# MEC1721N_B0_LJ register map
Vendor: Microchip Technology; Series: MEC172x; File version: 0
CPU: CM4 r1p0, little endian, MPU, FPU, 3 interrupt priority bits, 172 interrupts
Registers are 32-bit, read-write, reset 0x0 unless marked. A register's access mark holds for its fields unless they carry their own. Offsets are from the block's base; [hi:lo] are bit positions.

## TFDP — The TFDP serially transmits EC-originated diagnostic vectors to an external debug trace system.
Base 0x40008C00
0x00 MSDATA 8-bit — Debug data to be shifted out on the TFDP Debug port. While data is being shifted out, the Host Interface will 'hold-off' additional writes to the data register until the transfer is complete.
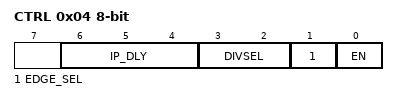
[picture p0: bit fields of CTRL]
0x04 CTRL 8-bit — Debug Control Register
  [6:4] IP_DLY — Inter-packet Delay. The delay is in terms of TFDP Debug output clocks.
  [3:2] DIVSEL — Clock Divider Select.
  [1] EDGE_SEL — 1= Data is shifted out on the falling edge of the debug clock, 0= Data is shifted out on the rising edge of the debug clock (Default)
  [0] EN — Enable. 1=Clock enabled, 0=Clock is disabled (Default)

## PORT_80_DEBUG — Diagnostic data is written by the Host Interface to the Port 80 BIOS Debug Port.
Base 0x400F8000
0x00 HOST_DATA32 wo — Host Data Register
  [31:0] H_DAT — This is the host data.
0x100 EC_DATA 8-bit ro
  [7:0] EC_DATA — This is the Oldest FIFO byte from the Host.
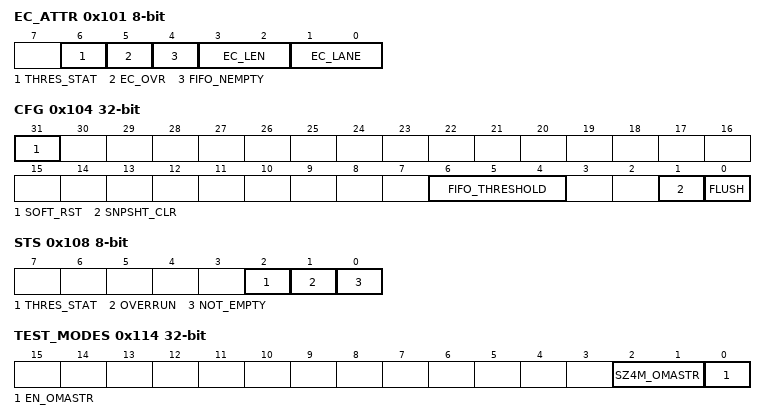
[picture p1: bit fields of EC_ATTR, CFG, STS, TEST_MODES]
0x101 EC_ATTR 8-bit ro — EC Attribute Register.
  [6] THRES_STAT — Threshold Status
  [5] EC_OVR — FIFO Overflow 1 = One or more bytes have been lost from the FIFO before this byte. 0 = No loss of information has occurred immediately before this byte.
  [4] FIFO_NEMPTY — FIFO Not Empty Status
  [3:2] EC_LEN — Length 00 = One byte, or a continuation of a multi-byte value. 01 = The first byte (LSB) of a two-byte value. 10 = The first byte (LSB) of a 4-byte value. 11 = Invalid
  [1:0] EC_LANE — The byte address to which this byte was written 00 = Byte Lane 0 01 = Byte Lane 1 10 = Byte Lane 2 11 = Byte Lane 3
0x104 CFG — Configuration Register.
  [31] SOFT_RST — Soft Reset, When a 1 is written to this bit a one clock wide pulse resets the entire block
  [6:4] FIFO_THRESHOLD — This field determines the threshold for the Port 80 32-Bit BIOS Debug Port Interrupts. 7=30 entry threshold 6=28 entry threshold 5=24 entry threshold 4=20 entry threshold 3=16 entry threshold 2=8 entry threshold 1=4 entry threshold 0=1 entry threshold
  [1] SNPSHT_CLR — Writing this bit clears the Snapshot Register as well as the Capture Register (Buffer).
  [0] FLUSH — Flush FIFO (also clears the OVERRUN bit) Self Clearing bit. This bit does not affect the Snapshot Register.
0x108 STS 8-bit ro — Status Register
  [2] THRES_STAT — Threshold Status is set when the number of threshold entries are above the selected threshold
  [1] OVERRUN — The OVERRUN bit is 1 when the host writes the Host Data Register when the FIFO is full.
  [0] NOT_EMPTY — The NOT EMPTY bit is 1 when there is data in the FIFO. The NOT EMPTY bit is 0 when the FIFO is empty.
0x109 INT_EN 8-bit — Interrupt Enable Register
  [0] THRES_IEN — Enable Threshold interrupt. When set threshold interrupt is enabled
0x10C SNAPSHOT ro
  [31:0] SNAPSHOT — Current image of the 4-byte Port 80 value, captured immediately from the Host CPU.
0x110 CAPTURE ro
  [31:0] CAPTURE — Current image of the 4-byte Port 80 value capture register.
0x114 TEST_MODES ro — Test Mode Register
  [2:1] SZ4M_OMASTR — Size from other master 00 = Byte 01 = Word 10 = Double Word 11 = Invalid
  [0] EN_OMASTR — Enable other masters (JTAG, EC etc) to be able to write to Port80 FIFO with size selection.
0x330 ACTIVATE32 — Activate Register
  [0] ACT — When this bit is asserted 1, the block is enabled. When this bit is 0, writes by the Host interface to the Host Data Register are not claimed, the FIFO is flushed.
0x400 HOST_DATA8 8-bit wo — Host Data Register
  [7:0] HOST_DATA — This is the host data.
0x730 ACTIVATE8 8-bit — Activate Register
  [0] ACTIVATE — When this bit is asserted 1, the block is enabled. When this bit is 0, writes by the Host interface to the Host Data Register are not claimed, the FIFO is flushed.
0x7F0 HST_ALIS_DATA 8-bit — Host Alias Data Register
  [1:0] ALIS_BLANE — Byte from Alias LDN Port80 mapped location in Snapshot Register b00 = Byte 0 b01 = Byte 1 b10 = Byte 2 b11 = Byte 3
